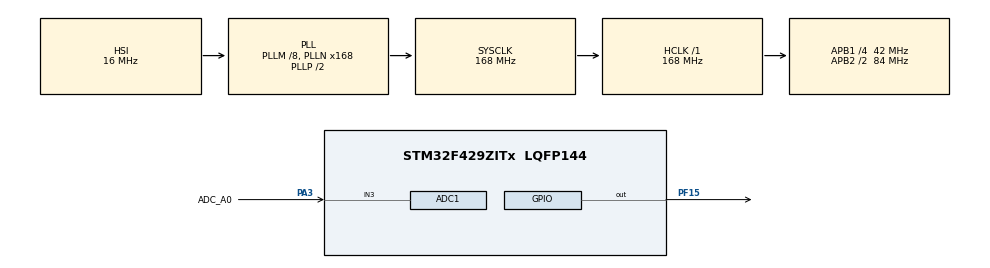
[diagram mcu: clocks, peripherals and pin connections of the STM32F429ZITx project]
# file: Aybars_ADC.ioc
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ADC1.Channel-0\#ChannelRegularConversion=ADC_CHANNEL_3
ADC1.ContinuousConvMode=ENABLE
ADC1.EOCSelection=ADC_EOC_SEQ_CONV
ADC1.NbrOfConversionFlag=1
ADC1.Rank-0\#ChannelRegularConversion=1
ADC1.SamplingTime-0\#ChannelRegularConversion=ADC_SAMPLETIME_3CYCLES
ADC1.master=1
Mcu.Family=STM32F4
Mcu.Name=STM32F429ZITx
Mcu.Package=LQFP144
NVIC.ADC_IRQn=true\:0\:0\:false\:false\:true\:true\:true
NVIC.PriorityGroup=NVIC_PRIORITYGROUP_4
PA3.GPIO_Label=ADC_A0
PA3.Signal=ADCx_IN3
PC14/OSC32_IN.Mode=LSE-External-Oscillator
PC14/OSC32_IN.Signal=RCC_OSC32_IN
PC15/OSC32_OUT.Mode=LSE-External-Oscillator
PC15/OSC32_OUT.Signal=RCC_OSC32_OUT
PF15.Signal=GPIO_Output
PH0/OSC_IN.Mode=HSE-External-Oscillator
PH0/OSC_IN.Signal=RCC_OSC_IN
PH1/OSC_OUT.Mode=HSE-External-Oscillator
PH1/OSC_OUT.Signal=RCC_OSC_OUT
ProjectManager.HeapSize=0x200
ProjectManager.StackSize=0x400
ProjectManager.TargetToolchain=STM32CubeIDE
RCC.48MHZClocksFreq_Value=84000000
RCC.AHBFreq_Value=168000000
RCC.APB1CLKDivider=RCC_HCLK_DIV4
RCC.APB1Freq_Value=42000000
RCC.APB1TimFreq_Value=84000000
RCC.APB2CLKDivider=RCC_HCLK_DIV2
RCC.APB2Freq_Value=84000000
RCC.APB2TimFreq_Value=168000000
RCC.CortexFreq_Value=168000000
RCC.HCLKFreq_Value=168000000
RCC.HSE_VALUE=25000000
RCC.HSI_VALUE=16000000
RCC.PLLM=8
RCC.PLLN=168
RCC.SYSCLKFreq_VALUE=168000000
RCC.SYSCLKSource=RCC_SYSCLKSOURCE_PLLCLK
RCC.VCOOutputFreq_Value=336000000
SH.ADCx_IN3.0=ADC1_IN3,IN3
board=custom

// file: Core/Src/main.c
/* USER CODE BEGIN Header */
/**
  ******************************************************************************
  * @file           : main.c
  * @brief          : Main program body
  ******************************************************************************
  * @attention
  *
  * <h2><center>&copy; Copyright (c) 2021 STMicroelectronics.
  * All rights reserved.</center></h2>
  *
  * This software component is licensed by ST under BSD 3-Clause license,
  * the "License"; You may not use this file except in compliance with the
  * License. You may obtain a copy of the License at:
  *                        opensource.org/licenses/BSD-3-Clause
  *
  ******************************************************************************
  */
/* USER CODE END Header */
#include "main.h"

/* USER CODE BEGIN Includes */
#include<stdio.h>
#include<string.h>
/* USER CODE END Includes */

ADC_HandleTypeDef hadc1;

/* USER CODE BEGIN PV */
uint16_t raw;
/* USER CODE END PV */

void SystemClock_Config(void);
static void MX_GPIO_Init(void);
static void MX_ADC1_Init(void);
/* USER CODE BEGIN PFP */
//void DMATransferComplete(DMA_HandleTypeDef *hdma);
/* USER CODE END PFP */

/* USER CODE BEGIN 0 */
void HAL_ADC_ConvCpltCallback(ADC_HandleTypeDef* hadc){
raw = HAL_ADC_GetValue(&hadc1);
}
/* USER CODE END 0 */

int main(void)
{
  /* USER CODE BEGIN 1 */
	//uint16_t raw;
	char msg[10];
  /* USER CODE END 1 */

  /* MCU Configuration--------------------------------------------------------*/

  /* Reset of all peripherals, Initializes the Flash interface and the Systick. */
  HAL_Init();

  /* Configure the system clock */
  SystemClock_Config();

  /* Initialize all configured peripherals */
  MX_GPIO_Init();
  MX_ADC1_Init();
  /* USER CODE BEGIN 2 */
  HAL_ADC_Start_IT(&hadc1);
  /* USER CODE END 2 */

  /* Infinite loop */
  /* USER CODE BEGIN WHILE */
  while (1)
  {
	  //Test: Set GPIO pin high
	  HAL_GPIO_WritePin(GPIOA, GPIO_PIN_3, GPIO_PIN_SET);

	  //Get ADC Value

	//  HAL_ADC_PollForConversion(&hadc1, HAL_MAX_DELAY);
	 // raw = HAL_ADC_GetValue(&hadc1);

	  //Test: Set GPIO pin low
	 // HAL_GPIO_WritePin(GPIOA, GPIO_Pin_3, GPIO_PIN_RESET);

	  //Convert to string and print

    /* USER CODE END WHILE */

  }
}

void SystemClock_Config(void)
{
  RCC_OscInitTypeDef RCC_OscInitStruct = {0};
  RCC_ClkInitTypeDef RCC_ClkInitStruct = {0};

  /** Configure the main internal regulator output voltage
  */
  __HAL_RCC_PWR_CLK_ENABLE();
  __HAL_PWR_VOLTAGESCALING_CONFIG(PWR_REGULATOR_VOLTAGE_SCALE1);
  /** Initializes the RCC Oscillators according to the specified parameters
  * in the RCC_OscInitTypeDef structure.
  */
  RCC_OscInitStruct.OscillatorType = RCC_OSCILLATORTYPE_HSI;
  RCC_OscInitStruct.HSIState = RCC_HSI_ON;
  RCC_OscInitStruct.HSICalibrationValue = RCC_HSICALIBRATION_DEFAULT;
  RCC_OscInitStruct.PLL.PLLState = RCC_PLL_ON;
  RCC_OscInitStruct.PLL.PLLSource = RCC_PLLSOURCE_HSI;
  RCC_OscInitStruct.PLL.PLLM = 8;
  RCC_OscInitStruct.PLL.PLLN = 168;
  RCC_OscInitStruct.PLL.PLLP = RCC_PLLP_DIV2;
  RCC_OscInitStruct.PLL.PLLQ = 4;
  if (HAL_RCC_OscConfig(&RCC_OscInitStruct) != HAL_OK)
  {
    Error_Handler();
  }
  /** Initializes the CPU, AHB and APB buses clocks
  */
  RCC_ClkInitStruct.ClockType = RCC_CLOCKTYPE_HCLK|RCC_CLOCKTYPE_SYSCLK
                              |RCC_CLOCKTYPE_PCLK1|RCC_CLOCKTYPE_PCLK2;
  RCC_ClkInitStruct.SYSCLKSource = RCC_SYSCLKSOURCE_PLLCLK;
  RCC_ClkInitStruct.AHBCLKDivider = RCC_SYSCLK_DIV1;
  RCC_ClkInitStruct.APB1CLKDivider = RCC_HCLK_DIV4;
  RCC_ClkInitStruct.APB2CLKDivider = RCC_HCLK_DIV2;

  if (HAL_RCC_ClockConfig(&RCC_ClkInitStruct, FLASH_LATENCY_5) != HAL_OK)
  {
    Error_Handler();
  }
}

static void MX_ADC1_Init(void)
{

  ADC_ChannelConfTypeDef sConfig = {0};

  /** Configure the global features of the ADC (Clock, Resolution, Data Alignment and number of conversion)
  */
  hadc1.Instance = ADC1;
  hadc1.Init.ClockPrescaler = ADC_CLOCK_SYNC_PCLK_DIV4;
  hadc1.Init.Resolution = ADC_RESOLUTION_12B;
  hadc1.Init.ScanConvMode = DISABLE;
  hadc1.Init.ContinuousConvMode = ENABLE;
  hadc1.Init.DiscontinuousConvMode = DISABLE;
  hadc1.Init.ExternalTrigConvEdge = ADC_EXTERNALTRIGCONVEDGE_NONE;
  hadc1.Init.ExternalTrigConv = ADC_SOFTWARE_START;
  hadc1.Init.DataAlign = ADC_DATAALIGN_RIGHT;
  hadc1.Init.NbrOfConversion = 1;
  hadc1.Init.DMAContinuousRequests = DISABLE;
  hadc1.Init.EOCSelection = ADC_EOC_SEQ_CONV;
  if (HAL_ADC_Init(&hadc1) != HAL_OK)
  {
    Error_Handler();
  }
  /** Configure for the selected ADC regular channel its corresponding rank in the sequencer and its sample time.
  */
  sConfig.Channel = ADC_CHANNEL_3;
  sConfig.Rank = 1;
  sConfig.SamplingTime = ADC_SAMPLETIME_3CYCLES;
  if (HAL_ADC_ConfigChannel(&hadc1, &sConfig) != HAL_OK)
  {
    Error_Handler();
  }

}

static void MX_GPIO_Init(void)
{
  GPIO_InitTypeDef GPIO_InitStruct = {0};

  /* GPIO Ports Clock Enable */
  __HAL_RCC_GPIOC_CLK_ENABLE();
  __HAL_RCC_GPIOH_CLK_ENABLE();
  __HAL_RCC_GPIOA_CLK_ENABLE();
  __HAL_RCC_GPIOF_CLK_ENABLE();

  /*Configure GPIO pin Output Level */
  HAL_GPIO_WritePin(GPIOF, GPIO_PIN_15, GPIO_PIN_RESET);

  /*Configure GPIO pin : PF15 */
  GPIO_InitStruct.Pin = GPIO_PIN_15;
  GPIO_InitStruct.Mode = GPIO_MODE_OUTPUT_PP;
  GPIO_InitStruct.Pull = GPIO_NOPULL;
  GPIO_InitStruct.Speed = GPIO_SPEED_FREQ_LOW;
  HAL_GPIO_Init(GPIOF, &GPIO_InitStruct);

}

void Error_Handler(void)
{
  __disable_irq();
  while (1)
  {
  }
}

/************************ (C) COPYRIGHT STMicroelectronics *****END OF FILE****/
